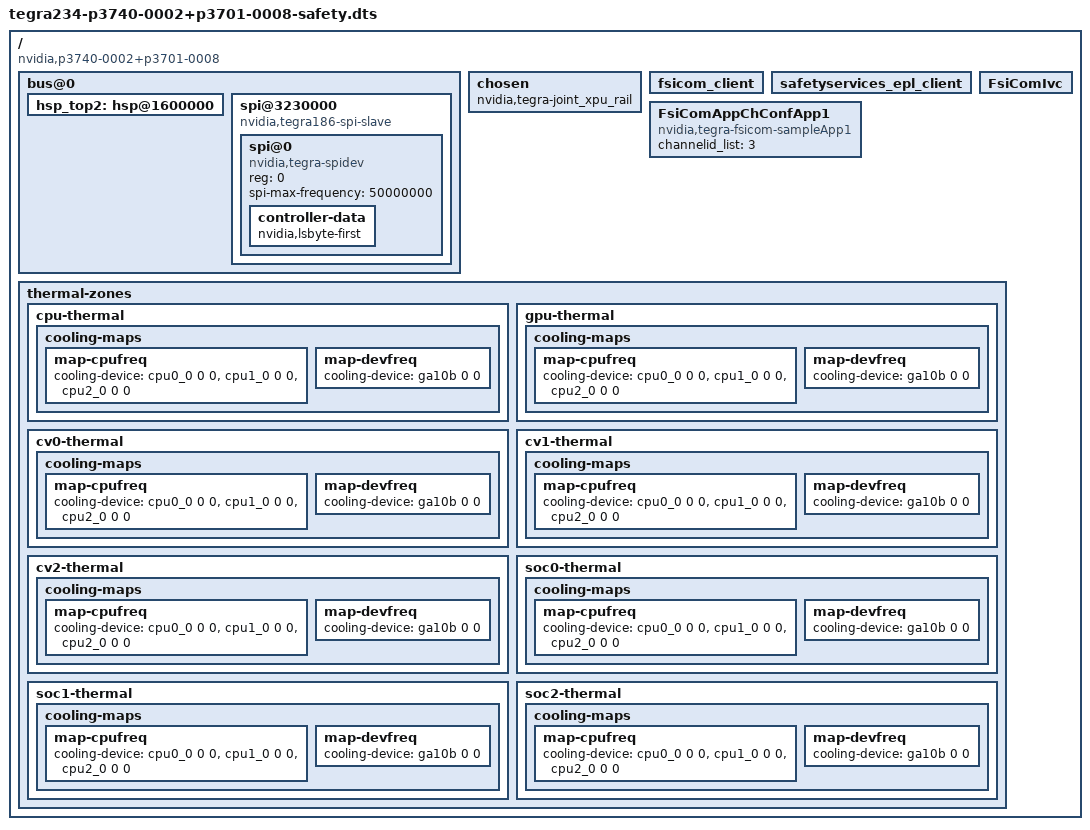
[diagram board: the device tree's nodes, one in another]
// SPDX-License-Identifier: GPL-2.0
// Copyright (c) 2023, NVIDIA CORPORATION & AFFILIATES.  All rights reserved.


/dts-v1/;
/plugin/;

#include "tegra234-soc-safetyservice-fsicom.dtsi"

/ {
	fragment-t234-p3740-p3701-safety@0 {
		target-path = "/";
		__overlay__ {
			compatible = "nvidia,p3740-0002+p3701-0008", "safety", "nvidia,p3701-0008", "nvidia,tegra234";

			bus@0 {
				hsp_top2: hsp@1600000 {
					status = "okay";
				};
				spi@3230000  {
					compatible = "nvidia,tegra186-spi-slave";
					status = "okay";
					spi@0 {
						compatible = "nvidia,tegra-spidev";
						reg = <0>;
						spi-max-frequency = <50000000>;
						controller-data {
							nvidia,lsbyte-first;
						};
					};
				};
			};

			chosen {
				/*
				 * The ideal approach for disabling rail-gating
				 * for GPU should be deleting the power-domains
				 * property in GPU node. But /delete-property/
				 * is not a valid syntax in the device tree
				 * overlay, the nvidia,tegra-joint_xpu_rail is
				 * specified to achieve the same as an
				 * alternative.
				 */
				nvidia,tegra-joint_xpu_rail;
			};
		};
	};

	fragment-t234-p3740-p3701-safety@1 {
		target-path = "/";
		__overlay__ {
			fsicom_client {
				status = "okay";
			};

			safetyservices_epl_client {
				/* userspace app uses this driver to send error code */
				status = "okay";
			};

			FsiComIvc {
				status = "okay";
			};

			/* FSI<->CCPLEX Communication through DRAM Carveout demo app */
			FsiComAppChConfApp1 {
				compatible = "nvidia,tegra-fsicom-sampleApp1";
				status = "okay";
				channelid_list = <3>;
			};
		};
	};

	fragment-t234-p3740-p3701-safety@2 {
		target-path = "/";
		__overlay__ {
			thermal-zones {
				cpu-thermal {
					cooling-maps {
						map-cpufreq {
							cooling-device = <&cpu0_0 0 0>,
									 <&cpu1_0 0 0>,
									 <&cpu2_0 0 0>;
						};

						map-devfreq {
							cooling-device = <&ga10b 0 0>;
						};
					};
				};

				gpu-thermal {
					cooling-maps {
						map-cpufreq {
							cooling-device = <&cpu0_0 0 0>,
									 <&cpu1_0 0 0>,
									 <&cpu2_0 0 0>;
						};

						map-devfreq {
							cooling-device = <&ga10b 0 0>;
						};
					};
				};

				cv0-thermal {
					cooling-maps {
						map-cpufreq {
							cooling-device = <&cpu0_0 0 0>,
									 <&cpu1_0 0 0>,
									 <&cpu2_0 0 0>;
						};

						map-devfreq {
							cooling-device = <&ga10b 0 0>;
						};
					};
				};

				cv1-thermal {
					cooling-maps {
						map-cpufreq {
							cooling-device = <&cpu0_0 0 0>,
									 <&cpu1_0 0 0>,
									 <&cpu2_0 0 0>;
						};

						map-devfreq {
							cooling-device = <&ga10b 0 0>;
						};
					};
				};

				cv2-thermal {
					cooling-maps {
						map-cpufreq {
							cooling-device = <&cpu0_0 0 0>,
									 <&cpu1_0 0 0>,
									 <&cpu2_0 0 0>;
						};

						map-devfreq {
							cooling-device = <&ga10b 0 0>;
						};
					};
				};

				soc0-thermal {
					cooling-maps {
						map-cpufreq {
							cooling-device = <&cpu0_0 0 0>,
									 <&cpu1_0 0 0>,
									 <&cpu2_0 0 0>;
						};

						map-devfreq {
							cooling-device = <&ga10b 0 0>;
						};
					};
				};

				soc1-thermal {
					cooling-maps {
						map-cpufreq {
							cooling-device = <&cpu0_0 0 0>,
									 <&cpu1_0 0 0>,
									 <&cpu2_0 0 0>;
						};

						map-devfreq {
							cooling-device = <&ga10b 0 0>;
						};
					};
				};

				soc2-thermal {
					cooling-maps {
						map-cpufreq {
							cooling-device = <&cpu0_0 0 0>,
									 <&cpu1_0 0 0>,
									 <&cpu2_0 0 0>;
						};

						map-devfreq {
							cooling-device = <&ga10b 0 0>;
						};
					};
				};
			};
		};
	};
};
